# STM32L15xxE register map
File version: 1.0
Registers are 32-bit, read-write, reset 0x0 unless marked. A register's access mark holds for its fields unless they carry their own. Offsets are from the block's base; [hi:lo] are bit positions; {n}, {i} and the like mark numbered series; 'fields as' and 'values as' point back to an identical list.

## WWDG — Window watchdog
Base 0x40002C00
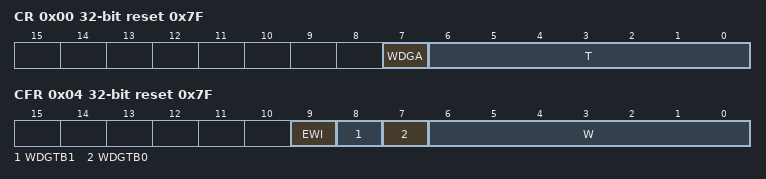
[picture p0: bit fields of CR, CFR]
0x00 CR access per field reset 0x7F — Control register
  [7] WDGA wo — Activation bit
  [6:0] T rw — 7-bit counter (MSB to LSB)
0x04 CFR access per field reset 0x7F — Configuration register
  [9] EWI wo — Early wakeup interrupt
  [8] WDGTB1 rw — Timer base
  [7] WDGTB0 rw
  [6:0] W rw — 7-bit window value
0x08 SR
  [0] EWIF

## DMA1 — Direct memory access controller
Base 0x40026000
Same registers: DMA2 0x40026400
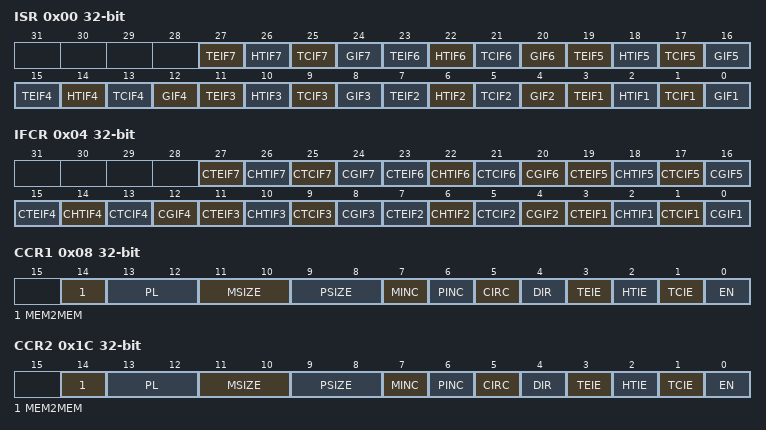
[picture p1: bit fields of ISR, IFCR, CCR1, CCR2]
0x00 ISR ro — interrupt status register
  [4n-1] TEIF{n} (n=1..7) — Channel x transfer error flag (x = 1 ..7)
  [4n-2] HTIF{n} (n=1..7) — Channel x half transfer flag (x = 1 ..7)
  [4n-3] TCIF{n} (n=1..7) — Channel x transfer complete flag (x = 1 ..7)
  [4n-4] GIF{n} (n=1..7) — Channel x global interrupt flag (x = 1 ..7)
0x04 IFCR wo — interrupt flag clear register
  [4n-1] CTEIF{n} (n=1..7) — Channel x transfer error clear (x = 1 ..7)
  [4n-2] CHTIF{n} (n=1..7) — Channel x half transfer clear (x = 1 ..7)
  [4n-3] CTCIF{n} (n=1..7) — Channel x transfer complete clear (x = 1 ..7)
  [4n-4] CGIF{n} (n=1..7) — Channel x global interrupt clear (x = 1 ..7)
0x08 CCR1 — channel x configuration register
  [14] MEM2MEM — Memory to memory mode
  [13:12] PL — Channel priority level
  [11:10] MSIZE — Memory size
  [9:8] PSIZE — Peripheral size
  [7] MINC — Memory increment mode
  [6] PINC — Peripheral increment mode
  [5] CIRC — Circular mode
  [4] DIR — Data transfer direction
  [3] TEIE — Transfer error interrupt enable
  [2] HTIE — Half transfer interrupt enable
  [1] TCIE — Transfer complete interrupt enable
  [0] EN — Channel enable
0x0C CNDTR1 — channel x number of data register
  [15:0] NDT — Number of data to transfer
0x10 CPAR1 — channel x peripheral address register
  [31:0] PA — Peripheral address
{0x0+0x14*i} CMAR{i} (i=1..7) — channel x memory address register
  [31:0] MA — Memory address
0x1C CCR2 — channel x configuration register
  fields as CCR1
0x20 CNDTR2 — channel x number of data register
  [15:0] NDT — Number of data to transfer
0x24 CPAR2 — channel x peripheral address register
  [31:0] PA — Peripheral address
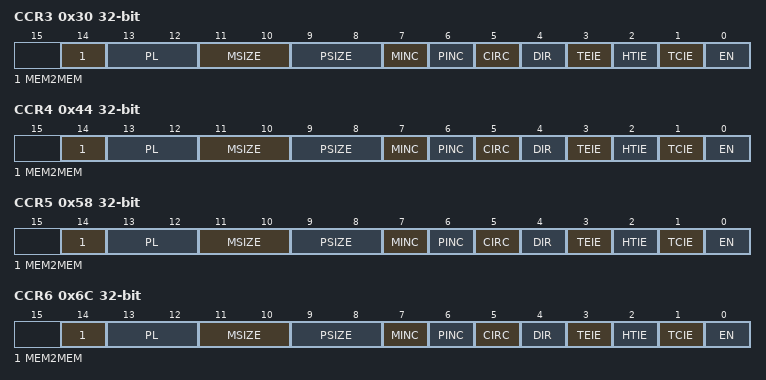
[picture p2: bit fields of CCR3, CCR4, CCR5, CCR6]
0x30 CCR3 — channel x configuration register
  fields as CCR1
0x34 CNDTR3 — channel x number of data register
  [15:0] NDT — Number of data to transfer
0x38 CPAR3 — channel x peripheral address register
  [31:0] PA — Peripheral address
0x44 CCR4 — channel x configuration register
  fields as CCR1
0x48 CNDTR4 — channel x number of data register
  [15:0] NDT — Number of data to transfer
0x4C CPAR4 — channel x peripheral address register
  [31:0] PA — Peripheral address
0x58 CCR5 — channel x configuration register
  fields as CCR1
0x5C CNDTR5 — channel x number of data register
  [15:0] NDT — Number of data to transfer
0x60 CPAR5 — channel x peripheral address register
  [31:0] PA — Peripheral address
0x6C CCR6 — channel x configuration register
  fields as CCR1
0x70 CNDTR6 — channel x number of data register
  [15:0] NDT — Number of data to transfer
0x74 CPAR6 — channel x peripheral address register
  [31:0] PA — Peripheral address
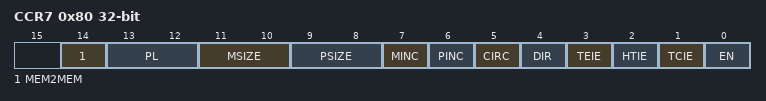
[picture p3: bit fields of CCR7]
0x80 CCR7 — channel x configuration register
  fields as CCR1
0x84 CNDTR7 — channel x number of data register
  [15:0] NDT — Number of data to transfer
0x88 CPAR7 — channel x peripheral address register
  [31:0] PA — Peripheral address

## NVIC — Nested Vectored Interrupt Controller
Base 0xE000E000
0x04 ICTR ro — Interrupt Controller Type Register
  [3:0] INTLINESNUM — Total number of interrupt lines in groups
0x100 ISER0 — Interrupt Set-Enable Register
  [31:0] SETENA
0x104 ISER1 — Interrupt Set-Enable Register
  [31:0] SETENA
0x180 ICER0 — Interrupt Clear-Enable Register
  [31:0] CLRENA
0x184 ICER1 — Interrupt Clear-Enable Register
  [31:0] CLRENA
0x200 ISPR0 — Interrupt Set-Pending Register
  [31:0] SETPEND
0x204 ISPR1 — Interrupt Set-Pending Register
  [31:0] SETPEND
0x280 ICPR0 — Interrupt Clear-Pending Register
  [31:0] CLRPEND
0x284 ICPR1 — Interrupt Clear-Pending Register
  [31:0] CLRPEND
0x300 IABR0 ro — Interrupt Active Bit Register
  [31:0] ACTIVE
0x304 IABR1 ro — Interrupt Active Bit Register
  [31:0] ACTIVE
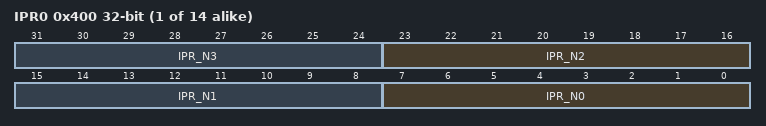
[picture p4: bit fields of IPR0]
{0x400+4i} IPR{i} (i=0..13) — Interrupt Priority Register
  [8n+7:8n] IPR_N{n} (n=0..3)
0xF00 STIR wo — Software Triggered Interrupt Register
  [8:0] INTID — interrupt to be triggered
